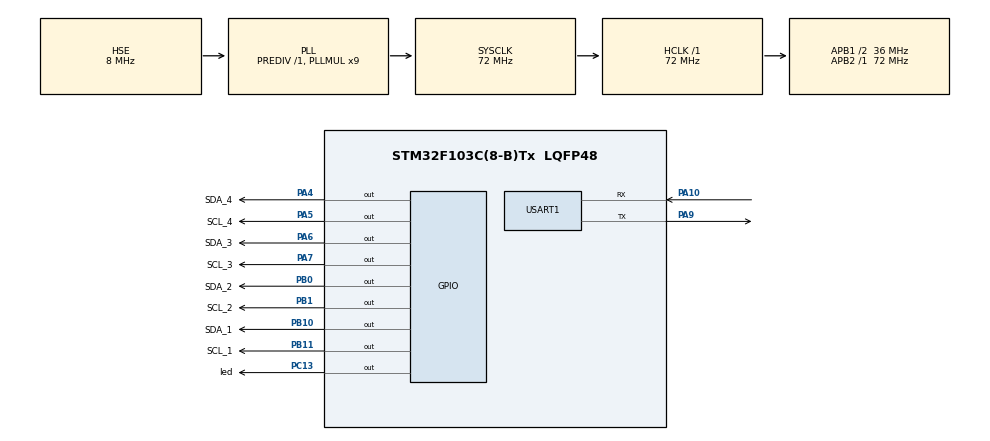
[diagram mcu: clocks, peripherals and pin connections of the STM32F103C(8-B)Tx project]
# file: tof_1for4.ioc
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Dma.Request0=USART1_RX
Dma.Request1=USART1_TX
Dma.USART1_RX.0.Direction=DMA_PERIPH_TO_MEMORY
Dma.USART1_RX.0.Instance=DMA1_Channel5
Dma.USART1_RX.0.MemDataAlignment=DMA_MDATAALIGN_BYTE
Dma.USART1_RX.0.MemInc=DMA_MINC_ENABLE
Dma.USART1_RX.0.Mode=DMA_NORMAL
Dma.USART1_RX.0.PeriphDataAlignment=DMA_PDATAALIGN_BYTE
Dma.USART1_RX.0.PeriphInc=DMA_PINC_DISABLE
Dma.USART1_RX.0.Priority=DMA_PRIORITY_LOW
Dma.USART1_TX.1.Direction=DMA_MEMORY_TO_PERIPH
Dma.USART1_TX.1.Instance=DMA1_Channel4
Dma.USART1_TX.1.MemDataAlignment=DMA_MDATAALIGN_BYTE
Dma.USART1_TX.1.MemInc=DMA_MINC_ENABLE
Dma.USART1_TX.1.Mode=DMA_NORMAL
Dma.USART1_TX.1.PeriphDataAlignment=DMA_PDATAALIGN_BYTE
Dma.USART1_TX.1.PeriphInc=DMA_PINC_DISABLE
Dma.USART1_TX.1.Priority=DMA_PRIORITY_LOW
FREERTOS.Tasks01=defaultTask,24,128,StartDefaultTask,Default,NULL,Dynamic,NULL,NULL
Mcu.Family=STM32F1
Mcu.Name=STM32F103C(8-B)Tx
Mcu.Package=LQFP48
NVIC.DMA1_Channel4_IRQn=true\:5\:0\:false\:false\:true\:true\:false\:true\:true
NVIC.DMA1_Channel5_IRQn=true\:5\:0\:false\:false\:true\:true\:false\:true\:true
NVIC.PriorityGroup=NVIC_PRIORITYGROUP_4
NVIC.TIM4_IRQn=true\:15\:0\:false\:false\:true\:false\:false\:true\:true
NVIC.TimeBase=TIM4_IRQn
NVIC.TimeBaseIP=TIM4
NVIC.USART1_IRQn=true\:5\:0\:false\:false\:true\:true\:true\:true\:true
PA10.Mode=Asynchronous
PA10.Signal=USART1_RX
PA13.Mode=Serial_Wire
PA13.Signal=SYS_JTMS-SWDIO
PA14.Mode=Serial_Wire
PA14.Signal=SYS_JTCK-SWCLK
PA4.GPIO_Label=SDA_4
PA4.GPIO_ModeDefaultOutputPP=GPIO_MODE_OUTPUT_OD
PA4.GPIO_PuPd=GPIO_PULLUP
PA4.GPIO_Speed=GPIO_SPEED_FREQ_HIGH
PA4.Signal=GPIO_Output
PA5.GPIO_Label=SCL_4
PA5.GPIO_ModeDefaultOutputPP=GPIO_MODE_OUTPUT_OD
PA5.GPIO_PuPd=GPIO_PULLUP
PA5.GPIO_Speed=GPIO_SPEED_FREQ_HIGH
PA5.Signal=GPIO_Output
PA6.GPIO_Label=SDA_3
PA6.GPIO_ModeDefaultOutputPP=GPIO_MODE_OUTPUT_OD
PA6.GPIO_PuPd=GPIO_PULLUP
PA6.GPIO_Speed=GPIO_SPEED_FREQ_HIGH
PA6.Signal=GPIO_Output
PA7.GPIO_Label=SCL_3
PA7.GPIO_ModeDefaultOutputPP=GPIO_MODE_OUTPUT_OD
PA7.GPIO_PuPd=GPIO_PULLUP
PA7.GPIO_Speed=GPIO_SPEED_FREQ_HIGH
PA7.Signal=GPIO_Output
PA9.Mode=Asynchronous
PA9.Signal=USART1_TX
PB0.GPIO_Label=SDA_2
PB0.GPIO_ModeDefaultOutputPP=GPIO_MODE_OUTPUT_OD
PB0.GPIO_PuPd=GPIO_PULLUP
PB0.GPIO_Speed=GPIO_SPEED_FREQ_HIGH
PB0.Signal=GPIO_Output
PB1.GPIO_Label=SCL_2
PB1.GPIO_ModeDefaultOutputPP=GPIO_MODE_OUTPUT_OD
PB1.GPIO_PuPd=GPIO_PULLUP
PB1.GPIO_Speed=GPIO_SPEED_FREQ_HIGH
PB1.Signal=GPIO_Output
PB10.GPIO_Label=SDA_1
PB10.GPIO_ModeDefaultOutputPP=GPIO_MODE_OUTPUT_OD
PB10.GPIO_PuPd=GPIO_PULLUP
PB10.GPIO_Speed=GPIO_SPEED_FREQ_HIGH
PB10.Signal=GPIO_Output
PB11.GPIO_Label=SCL_1
PB11.GPIO_ModeDefaultOutputPP=GPIO_MODE_OUTPUT_OD
PB11.GPIO_PuPd=GPIO_PULLUP
PB11.GPIO_Speed=GPIO_SPEED_FREQ_HIGH
PB11.Signal=GPIO_Output
PC13-TAMPER-RTC.GPIO_Label=led
PC13-TAMPER-RTC.GPIO_Speed=GPIO_SPEED_FREQ_HIGH
PC13-TAMPER-RTC.Signal=GPIO_Output
PD0-OSC_IN.Mode=HSE-External-Oscillator
PD0-OSC_IN.Signal=RCC_OSC_IN
PD1-OSC_OUT.Mode=HSE-External-Oscillator
PD1-OSC_OUT.Signal=RCC_OSC_OUT
ProjectManager.HeapSize=0x200
ProjectManager.StackSize=0x400
ProjectManager.TargetToolchain=MDK-ARM V5.27
RCC.AHBFreq_Value=72000000
RCC.APB1CLKDivider=RCC_HCLK_DIV2
RCC.APB1Freq_Value=36000000
RCC.APB1TimFreq_Value=72000000
RCC.APB2Freq_Value=72000000
RCC.APB2TimFreq_Value=72000000
RCC.HCLKFreq_Value=72000000
RCC.PLLMUL=RCC_PLL_MUL9
RCC.PLLSourceVirtual=RCC_PLLSOURCE_HSE
RCC.SYSCLKFreq_VALUE=72000000
RCC.SYSCLKSource=RCC_SYSCLKSOURCE_PLLCLK
RCC.USBFreq_Value=72000000
TIM1.AutoReloadPreload=TIM_AUTORELOAD_PRELOAD_ENABLE
TIM1.Period=10000-1
TIM1.Prescaler=72-1
USART1.VirtualMode=VM_ASYNC
VP_FREERTOS_VS_CMSIS_V2.Mode=CMSIS_V2
VP_SYS_VS_tim4.Mode=TIM4
VP_TIM1_VS_ClockSourceINT.Mode=Internal
board=custom

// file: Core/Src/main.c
/* USER CODE BEGIN Header */
/**
  ******************************************************************************
  * @file           : main.c
  * @brief          : Main program body
  ******************************************************************************
  * @attention
  *
  * Copyright (c) 2026 STMicroelectronics.
  * All rights reserved.
  *
  * This software is licensed under terms that can be found in the LICENSE file
  * in the root directory of this software component.
  * If no LICENSE file comes with this software, it is provided AS-IS.
  *
  ******************************************************************************
  */
/* USER CODE END Header */
#include "main.h"
#include "cmsis_os.h"
#include "dma.h"
#include "tim.h"
#include "usart.h"
#include "gpio.h"

void SystemClock_Config(void);
void MX_FREERTOS_Init(void);

int main(void)
{

  /* MCU Configuration--------------------------------------------------------*/

  /* Reset of all peripherals, Initializes the Flash interface and the Systick. */
  HAL_Init();

  /* Configure the system clock */
  SystemClock_Config();

  /* Initialize all configured peripherals */
  MX_GPIO_Init();
  MX_DMA_Init();
  MX_USART1_UART_Init();
  MX_TIM1_Init();

  /* Init scheduler */
  osKernelInitialize();  /* Call init function for freertos objects (in cmsis_os2.c) */
  MX_FREERTOS_Init();

  /* Start scheduler */
  osKernelStart();

  /* We should never get here as control is now taken by the scheduler */

  /* Infinite loop */
  while (1)
  {

  }
}

void SystemClock_Config(void)
{
  RCC_OscInitTypeDef RCC_OscInitStruct = {0};
  RCC_ClkInitTypeDef RCC_ClkInitStruct = {0};

  /** Initializes the RCC Oscillators according to the specified parameters
  * in the RCC_OscInitTypeDef structure.
  */
  RCC_OscInitStruct.OscillatorType = RCC_OSCILLATORTYPE_HSE;
  RCC_OscInitStruct.HSEState = RCC_HSE_ON;
  RCC_OscInitStruct.HSEPredivValue = RCC_HSE_PREDIV_DIV1;
  RCC_OscInitStruct.HSIState = RCC_HSI_ON;
  RCC_OscInitStruct.PLL.PLLState = RCC_PLL_ON;
  RCC_OscInitStruct.PLL.PLLSource = RCC_PLLSOURCE_HSE;
  RCC_OscInitStruct.PLL.PLLMUL = RCC_PLL_MUL9;
  if (HAL_RCC_OscConfig(&RCC_OscInitStruct) != HAL_OK)
  {
    Error_Handler();
  }

  /** Initializes the CPU, AHB and APB buses clocks
  */
  RCC_ClkInitStruct.ClockType = RCC_CLOCKTYPE_HCLK|RCC_CLOCKTYPE_SYSCLK
                              |RCC_CLOCKTYPE_PCLK1|RCC_CLOCKTYPE_PCLK2;
  RCC_ClkInitStruct.SYSCLKSource = RCC_SYSCLKSOURCE_PLLCLK;
  RCC_ClkInitStruct.AHBCLKDivider = RCC_SYSCLK_DIV1;
  RCC_ClkInitStruct.APB1CLKDivider = RCC_HCLK_DIV2;
  RCC_ClkInitStruct.APB2CLKDivider = RCC_HCLK_DIV1;

  if (HAL_RCC_ClockConfig(&RCC_ClkInitStruct, FLASH_LATENCY_2) != HAL_OK)
  {
    Error_Handler();
  }
}

void HAL_TIM_PeriodElapsedCallback(TIM_HandleTypeDef *htim)
{
  if (htim->Instance == TIM4)
  {
    HAL_IncTick();
  }
}

void Error_Handler(void)
{
  __disable_irq();
  while (1)
  {
  }
}

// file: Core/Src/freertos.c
/* USER CODE BEGIN Header */
/**
  ******************************************************************************
  * File Name          : freertos.c
  * Description        : 4组软件I2C读取4个VL53L1X + 阻塞式UART发送HEX协议
  *                      含调试输出
  ******************************************************************************
  */
/* USER CODE END Header */

#include "FreeRTOS.h"
#include "task.h"
#include "main.h"
#include "cmsis_os.h"

/* USER CODE BEGIN Includes */
#include "usart.h"
#include "sw_i2c.h"
#include "vl53l1x.h"
#include <string.h>
/* USER CODE END Includes */

/* USER CODE BEGIN Variables */

/* HEX协议帧: [0xCC][d1_h][d1_l][d2_h][d2_l][d3_h][d3_l][d4_h][d4_l][0xEE] */
static uint8_t hex_frame[10];

/* USER CODE END Variables */

/* Definitions for AppTask */
osThreadId_t appTaskHandle;
const osThreadAttr_t appTask_attributes = {
  .name = "AppTask",
  .stack_size = 512 * 4,
  .priority = (osPriority_t) osPriorityNormal,
};

void AppTaskEntry(void *argument);

void MX_FREERTOS_Init(void);

void MX_FREERTOS_Init(void) {
  appTaskHandle = osThreadNew(AppTaskEntry, NULL, &appTask_attributes);
}

/**
  * @brief  组装HEX帧并通过阻塞式UART发送
  *         协议: [0xCC][ff_h][ff_l][fb_h][fb_l][bf_h][bf_l][bb_h][bb_l][0xEE]
  *         大端序: 高位在前, 低位在后
  */
static void send_hex_frame(uint16_t ff, uint16_t fb, uint16_t bf, uint16_t bb)
{
    hex_frame[0] = 0xCC;
    hex_frame[1] = (uint8_t)(ff >> 8);
    hex_frame[2] = (uint8_t)(ff & 0xFF);
    hex_frame[3] = (uint8_t)(fb >> 8);
    hex_frame[4] = (uint8_t)(fb & 0xFF);
    hex_frame[5] = (uint8_t)(bf >> 8);
    hex_frame[6] = (uint8_t)(bf & 0xFF);
    hex_frame[7] = (uint8_t)(bb >> 8);
    hex_frame[8] = (uint8_t)(bb & 0xFF);
    hex_frame[9] = 0xEE;

    HAL_UART_Transmit_DMA(&huart1, hex_frame, 10);
}

/**
  * @brief  AppTask: 4个ToF初始化 → 连续读取4个距离 → HEX帧发送 + LED心跳
  */
void AppTaskEntry(void *argument)
{
  /* 等待传感器上电稳定 */
  vTaskDelay(pdMS_TO_TICKS(2000));

  /* 初始化软件I2C (DWT延时) */
  SW_I2C_Init();

  /* 初始化4个VL53L1X */
  uint8_t init_ok[TOF_COUNT] = {0};
  for (int i = 0; i < TOF_COUNT; i++)
  {
    init_ok[i] = VL53L1X_Init(i, &sw_i2c_ch[i], VL53L1X_LONG_DISTANCE);
    debug_printf("[TOF%d] Init %s (err=%d)\r\n", i, init_ok[i] ? "FAIL" : "OK", init_ok[i]);
  }

  /* 主循环: 连续读取4个ToF, 发送HEX帧 */
//  int loop_count = 0;
  for(;;)
  {
    uint16_t dist[TOF_COUNT] = {0};
    for (int i = 0; i < TOF_COUNT; i++)
    {
      if (init_ok[i] == 0)
      {
        int16_t d = VL53L1X_GetDistance(i);
        dist[i] = (d >= 0) ? (uint16_t)d : 0;
      }
    }
    send_hex_frame(dist[0], dist[1], dist[2], dist[3]);

    /* LED心跳 */
    HAL_GPIO_TogglePin(GPIOC, GPIO_PIN_13);

    /* 让出CPU给FreeRTOS调度器 */
    //vTaskDelay(pdMS_TO_TICKS(1));
  }
}
